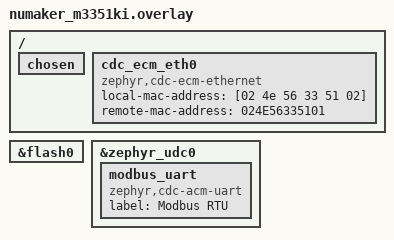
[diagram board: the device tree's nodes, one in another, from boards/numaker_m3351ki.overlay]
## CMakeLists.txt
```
cmake_minimum_required(VERSION 3.28)
find_package(Zephyr REQUIRED HINTS $ENV{ZEPHYR_BASE})
project(nv_modbus)
add_subdirectory(lib/modbus)
target_sources(app PRIVATE src/main.c src/demo_data.c src/usb.c src/network.c)
target_include_directories(app PRIVATE src)
```

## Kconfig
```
mainmenu "NK-M3351KI Modbus migration"

menu "Application"
config APP_MODBUS_CLIENT
	bool "Run master/client demonstration instead of server"
	default n
config APP_SEPARATE_REGIONS
	bool "Use the upstream separate-region example map"
	default n
config APP_LARGE_TEST_MAP
	bool "Enlarge shared map to 128 words for packet-boundary testing"
	depends on !APP_SEPARATE_REGIONS
	default n
config APP_USB_VID
	hex "Assigned application USB vendor ID"
	range 0x0 0xffff
	default 0
	help
	  Set your assigned identity in a private configuration overlay.
	  A zero identity permits compile checks but prevents USB startup.
config APP_USB_PID
	hex "Assigned application USB product ID"
	range 0x0 0xffff
	default 0
config APP_IP_ADDRESS
	string "Board private USB-network IPv4 address"
	default "192.168.77.2"
config APP_PEER_ADDRESS
	string "PC private USB-network IPv4 address"
	default "192.168.77.1"
config APP_PEER_PORT
	int "PC Modbus server TCP port"
	range 1 65535
	default 1502
config APP_QUERY_INTERVAL_MS
	int "Client query interval in milliseconds"
	range 10 60000
	default 100
endmenu

rsource "lib/modbus/Kconfig"
source "Kconfig.zephyr"
```

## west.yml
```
manifest:
  version: "1.2"
  projects:
    - name: zephyr
      url: https://github.com/zephyrproject-rtos/zephyr
      revision: 5c71a733110403a2e01f6cabd922b5f0198e9981
      path: .deps/zephyr
      west-commands: scripts/west-commands.yml
    - name: cmsis
      url: https://github.com/zephyrproject-rtos/cmsis
      revision: 512cc7e895e8491696b61f7ba8066b4a182569b8
      path: .deps/modules/hal/cmsis
    - name: cmsis_6
      url: https://github.com/zephyrproject-rtos/CMSIS_6
      revision: 1c1840af7a7e757d6e2fec3ddb0e5ce0dfcc93c8
      path: .deps/modules/hal/cmsis_6
    - name: hal_nuvoton
      url: https://github.com/zephyrproject-rtos/hal_nuvoton
      revision: 0f411a85da7d17a612d54450f608f4d30cdb971f
      path: .deps/modules/hal/nuvoton
  self:
    path: .
```

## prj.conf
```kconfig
CONFIG_SERIAL=y
CONFIG_UART_INTERRUPT_DRIVEN=y
CONFIG_UART_LINE_CTRL=y
CONFIG_CONSOLE=y
CONFIG_UART_CONSOLE=y
CONFIG_LOG=y
CONFIG_LOG_DEFAULT_LEVEL=3
CONFIG_LOG_BUFFER_SIZE=2048
CONFIG_USB_DEVICE_STACK_NEXT=y
CONFIG_CDC_ACM_SERIAL_INITIALIZE_AT_BOOT=n
CONFIG_HWINFO=y
CONFIG_NETWORKING=y
CONFIG_NET_L2_ETHERNET=y
# The pinned M3351 Zephyr port has no entropy driver. Isolated demo only.
CONFIG_TEST_RANDOM_GENERATOR=y
CONFIG_NET_IPV4=y
CONFIG_NET_IPV6=n
CONFIG_NET_TCP=y
CONFIG_NET_UDP=n
CONFIG_NET_SOCKETS=y
CONFIG_NET_MAX_CONTEXTS=10
CONFIG_NET_MAX_CONN=10
CONFIG_NET_PKT_RX_COUNT=12
CONFIG_NET_PKT_TX_COUNT=12
CONFIG_NET_BUF_RX_COUNT=32
CONFIG_NET_BUF_TX_COUNT=32
CONFIG_NET_BUF_DATA_SIZE=128
CONFIG_MAIN_STACK_SIZE=3072
CONFIG_SYSTEM_WORKQUEUE_STACK_SIZE=2048
CONFIG_HEAP_MEM_POOL_SIZE=8192
CONFIG_THREAD_NAME=y
CONFIG_INIT_STACKS=y
CONFIG_THREAD_STACK_INFO=y
CONFIG_USE_DT_CODE_PARTITION=n
```

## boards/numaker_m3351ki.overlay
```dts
/* SPDX-License-Identifier: Apache-2.0 */
/* The confirmed M3351KJCAE uses the upstream 1 MiB APROM map.
 * This application is a directly booted APROM image, not an MCUboot image.
 */
/ {
	chosen {
		/delete-property/ zephyr,code-partition;
	};
	cdc_ecm_eth0: cdc_ecm_eth0 {
		compatible = "zephyr,cdc-ecm-ethernet";
		local-mac-address = [02 4e 56 33 51 02];
		remote-mac-address = "024E56335101";
	};
};

&flash0 {
	/delete-node/ partitions;
};
&zephyr_udc0 {
	modbus_uart: modbus_uart {
		compatible = "zephyr,cdc-acm-uart";
		label = "Modbus RTU";
	};
};
```

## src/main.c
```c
/* SPDX-License-Identifier: Apache-2.0 */
#include "app.h"
#include <zephyr/logging/log.h>
#include <zephyr/net/net_ip.h>
#include <zephyr/sys/atomic.h>

LOG_MODULE_REGISTER(app, LOG_LEVEL_INF);
static modbusHandler_t rtu, tcp;
static atomic_t handlers_ready;
K_MUTEX_DEFINE(rtu_bank_lock);
K_MUTEX_DEFINE(tcp_bank_lock);

void app_transport_reset(bool reset_network)
{
    if (atomic_get(&handlers_ready)) {
        ModbusTransportReset(&rtu);
        if (reset_network) {
            ModbusTransportReset(&tcp);
        }
    }
}

static int start_handlers(void)
{
    int error;
    rtu.uModbusType = IS_ENABLED(CONFIG_APP_MODBUS_CLIENT) ? MB_MASTER : MB_SLAVE;
    rtu.xTypeHW = USB_CDC_HW;
    rtu.port = DEVICE_DT_GET(DT_NODELABEL(modbus_uart));
    rtu.u8id = IS_ENABLED(CONFIG_APP_MODBUS_CLIENT) ? 0 : 10;
    rtu.u16timeOut = 1000;
    rtu.memory_lock = &rtu_bank_lock;
    app_data_init(&rtu.memory, 0);

    tcp.uModbusType = rtu.uModbusType;
    tcp.xTypeHW = TCP_HW;
    tcp.u8id = IS_ENABLED(CONFIG_APP_MODBUS_CLIENT) ? 0 : 1;
    tcp.u16timeOut = 1000;
    tcp.uTcpPort = 502;
    tcp.tcp_idle_ms = 40000;
    tcp.memory_lock = &tcp_bank_lock;
    app_data_init(&tcp.memory, 1);

    error = ModbusInit(&rtu);
    if (error != 0) {
        return error;
    }
    error = ModbusInit(&tcp);
    if (error == 0) {
        error = ModbusStartCDC(&rtu);
    }
    if (error == 0) {
        error = ModbusStart(&tcp);
    }
    if (error != 0) {
        ModbusStop(&rtu);
        ModbusStop(&tcp);
        return error;
    }
    atomic_set(&handlers_ready, 1);
    return 0;
}

static void run_clients(void)
{
    static const uint8_t functions[] = {5, 1, 15, 2, 6, 3, 16, 4};
    struct net_in_addr peer;
    uint32_t cycle = 0;
    if (net_addr_pton(NET_AF_INET, CONFIG_APP_PEER_ADDRESS, &peer) != 0) {
        LOG_ERR("Invalid peer IPv4 address");
        return;
    }
    for (;;) {
        for (size_t i = 0; i < ARRAY_SIZE(functions); ++i) {
            for (unsigned int transport = 0; transport < 2; ++transport) {
                uint16_t data[4] = {1, 0x1234, 0x5678, 0xabcd};
                modbus_t request = {
                    .u8id = transport == 0 ? 10 : 1,
                    .u8fct = functions[i],
                    .u16RegAdd = app_data_address(functions[i]),
                    .u16CoilsNo = (functions[i] == 5 || functions[i] == 6) ? 1 : 4,
                    .u16reg = data,
                    .u16regCapacity = ARRAY_SIZE(data),
                    .u16Port = CONFIG_APP_PEER_PORT,
                    .xIpAddress = peer.s_addr,
                    .u8clientID = 0,
                };
                int result = ModbusQueryV2(transport == 0 ? &rtu : &tcp, request);
                LOG_INF("client cycle=%u transport=%s fc=%u result=%d data0=%u",
                        cycle, transport == 0 ? "rtu" : "tcp", functions[i],
                        result, data[0]);
                k_msleep(CONFIG_APP_QUERY_INTERVAL_MS);
            }
        }
        ++cycle;
    }
}

int main(void)
{
    int error = app_network_init();
    if (error == 0) {
        error = start_handlers();
    }
    if (error == 0) {
        error = app_usb_init();
    }
    if (error != 0) {
        atomic_clear(&handlers_ready);
        ModbusStop(&rtu);
        ModbusStop(&tcp);
        LOG_ERR("Startup failed: %d", error);
        return error;
    }
    LOG_INF("Modbus %s ready: RTU id10, TCP id1 port502",
            IS_ENABLED(CONFIG_APP_MODBUS_CLIENT) ? "client" : "server");
    if (IS_ENABLED(CONFIG_APP_MODBUS_CLIENT)) {
        run_clients();
    }
    return 0;
}
```

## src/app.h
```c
/* SPDX-License-Identifier: Apache-2.0 */
#ifndef NV_MODBUS_APP_H
#define NV_MODBUS_APP_H
#include "Modbus.h"

int app_usb_init(void);
int app_network_init(void);
void app_transport_reset(bool reset_network);
void app_data_init(mb_memory_t *memory, unsigned int bank);
uint16_t app_data_address(uint8_t function);
#endif
```

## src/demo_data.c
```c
/* SPDX-License-Identifier: Apache-2.0 */
#include "app.h"
#include <string.h>

static struct {
    uint16_t shared[IS_ENABLED(CONFIG_APP_LARGE_TEST_MAP) ? 128 : 16];
    uint16_t coils[2];
    uint16_t inputs[2];
    uint16_t holding[4];
    uint16_t registers[4];
} banks[2];

void app_data_init(mb_memory_t *memory, unsigned int bank)
{
    __ASSERT_NO_MSG(bank < ARRAY_SIZE(banks));
    memset(memory, 0, sizeof(*memory));
    if (IS_ENABLED(CONFIG_APP_SEPARATE_REGIONS)) {
        memory->u16coils = banks[bank].coils;
        memory->u16coilsStartAdd = 0;
        memory->u16coilsNregs = 2;
        memory->u16discreteInputs = banks[bank].inputs;
        memory->u16discreteInputsStartAdd = 100;
        memory->u16discreteInputsNregs = 2;
        memory->u16holdingRegs = banks[bank].holding;
        memory->u16holdingRegsStartAdd = 200;
        memory->u16holdingRegsNregs = 4;
        memory->u16inputRegs = banks[bank].registers;
        memory->u16inputRegsStartAdd = 300;
        memory->u16inputRegsNregs = 4;
    } else {
        memory->u16regs = banks[bank].shared;
        memory->u16regsize = ARRAY_SIZE(banks[bank].shared);
    }
}

uint16_t app_data_address(uint8_t function)
{
    if (!IS_ENABLED(CONFIG_APP_SEPARATE_REGIONS)) {
        return 0;
    }
    switch (function) {
    case 2: return 100;
    case 3:
    case 6:
    case 16: return 200;
    case 4: return 300;
    default: return 0;
    }
}
```

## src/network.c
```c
/* SPDX-License-Identifier: Apache-2.0 */
#include "app.h"
#include <errno.h>
#include <zephyr/logging/log.h>
#include <zephyr/net/net_if.h>
#include <zephyr/net/net_ip.h>

LOG_MODULE_REGISTER(app_network, LOG_LEVEL_INF);

int app_network_init(void)
{
    const struct device *device = DEVICE_DT_GET(DT_NODELABEL(cdc_ecm_eth0));
    struct net_in_addr address, netmask;
    struct net_if *iface;
    int error;

    if (!device_is_ready(device)) {
        return -ENODEV;
    }
    iface = net_if_lookup_by_dev(device);
    if (iface == NULL ||
        net_addr_pton(NET_AF_INET, CONFIG_APP_IP_ADDRESS, &address) != 0 ||
        net_addr_pton(NET_AF_INET, "255.255.255.0", &netmask) != 0) {
        return -EINVAL;
    }
    if (net_if_ipv4_addr_add(iface, &address, NET_ADDR_MANUAL, 0) == NULL ||
        !net_if_ipv4_set_netmask_by_addr(iface, &address, &netmask)) {
        return -ENOMEM;
    }
    error = net_if_up(iface);
    if (error != 0 && error != -EALREADY) {
        return error;
    }
    LOG_INF("USB network %s/24; no gateway", CONFIG_APP_IP_ADDRESS);
    return 0;
}
```

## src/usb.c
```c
/*
 * SPDX-License-Identifier: Apache-2.0
 * USB lifecycle adapted from Zephyr samples/subsys/usb/common/sample_usbd_init.c
 * Copyright (c) 2023 Nordic Semiconductor ASA
 */
#include "app.h"
#include <errno.h>
#include <zephyr/logging/log.h>
#include <zephyr/usb/usbd.h>
#include <zephyr/usb/class/usbd_cdc_acm.h>
#include <soc.h>

LOG_MODULE_REGISTER(app_usb, LOG_LEVEL_INF);
USBD_DEVICE_DEFINE(modbus_usb, DEVICE_DT_GET(DT_NODELABEL(zephyr_udc0)),
                   CONFIG_APP_USB_VID, CONFIG_APP_USB_PID);
USBD_DESC_LANG_DEFINE(language);
USBD_DESC_MANUFACTURER_DEFINE(manufacturer, "NV-Migration");
USBD_DESC_PRODUCT_DEFINE(product, "NK-M3351 Modbus RTU + TCP");
USBD_DESC_SERIAL_NUMBER_DEFINE(serial_number);
USBD_DESC_CONFIG_DEFINE(config_description, "Modbus serial and network");
USBD_CONFIGURATION_DEFINE(fs_configuration, 0, 50, &config_description);

static void cdc_session_reset(const struct device *dev, void *user_data)
{
    ARG_UNUSED(dev);
    ARG_UNUSED(user_data);
    app_transport_reset(false);
}

/*
 * The M335x devicetree leaves HXT off, so the USBD module and the PLL both run
 * from the factory-trimmed but otherwise free-running 48 MHz HIRC, and the
 * UDC driver does not trim it. Full-speed USB needs +/-0.25 %: without trim,
 * long IN packets with unfavourable bit patterns fail CRC at the host and the
 * controller retransmits the same DATA packet indefinitely (RTU "wedge").
 * Trim HIRC against USB SOF (TRM 6.2.10). Hardware clears FREQSEL when SOF is
 * missing for RETRYCNT loops, so re-arm on every reset/configuration/resume.
 */
static void hirc_trim_arm(void)
{
    SYS->HIRCTISTS = SYS_HIRCTISTS_TFAILIF_Msk | SYS_HIRCTISTS_CLKERRIF_Msk |
                     SYS_HIRCTISTS_OVBDIF_Msk;
    SYS->HIRCTCTL = (SYS->HIRCTCTL & SYS_HIRCTCTL_BOUNDARY_Msk) |
                    SYS_HIRCTCTL_REFCKSEL_Msk |
                    (3UL << SYS_HIRCTCTL_RETRYCNT_Pos) |
                    (3UL << SYS_HIRCTCTL_LOOPSEL_Pos) |
                    (1UL << SYS_HIRCTCTL_FREQSEL_Pos);
}

static void usb_message(struct usbd_context *const context,
                        const struct usbd_msg *const message)
{
    int error = 0;
    if (message->type == USBD_MSG_RESET || message->type == USBD_MSG_VBUS_REMOVED) {
        app_transport_reset(true);
    }
    if (message->type == USBD_MSG_RESET || message->type == USBD_MSG_CONFIGURATION ||
        message->type == USBD_MSG_RESUME) {
        hirc_trim_arm();
    }
    if (usbd_can_detect_vbus(context)) {
        if (message->type == USBD_MSG_VBUS_READY) {
            error = usbd_enable(context);
        } else if (message->type == USBD_MSG_VBUS_REMOVED) {
            error = usbd_disable(context);
        }
    }
    if (error != 0) {
        LOG_ERR("USB lifecycle error: %d", error);
    }
}

int app_usb_init(void)
{
    int error;
    if (CONFIG_APP_USB_VID == 0 || CONFIG_APP_USB_PID == 0) {
        LOG_ERR("Set assigned APP_USB_VID/PID before enabling USB");
        return -EINVAL;
    }
    struct usbd_desc_node *descriptors[] = {
        &language, &manufacturer, &product, &serial_number,
    };
    for (size_t i = 0; i < ARRAY_SIZE(descriptors); ++i) {
        error = usbd_add_descriptor(&modbus_usb, descriptors[i]);
        if (error != 0) {
            return error;
        }
    }
    error = usbd_add_configuration(&modbus_usb, USBD_SPEED_FS, &fs_configuration);
    if (error != 0) {
        return error;
    }
    error = usbd_register_class(&modbus_usb, "cdc_acm_0", USBD_SPEED_FS, 1);
    if (error != 0) {
        return error;
    }
    error = usbd_register_class(&modbus_usb, "cdc_ecm_0", USBD_SPEED_FS, 1);
    if (error != 0) {
        return error;
    }
    usbd_device_set_code_triple(&modbus_usb, USBD_SPEED_FS,
                               USB_BCC_MISCELLANEOUS, 0x02, 0x01);
    usbd_self_powered(&modbus_usb, false);
    error = usbd_cdc_acm_set_session_cb(DEVICE_DT_GET(DT_NODELABEL(modbus_uart)),
                                       cdc_session_reset, NULL);
    if (error != 0) {
        return error;
    }
    error = usbd_msg_register_cb(&modbus_usb, usb_message);
    if (error == 0) {
        error = usbd_init(&modbus_usb);
    }
    if (error == 0 && !usbd_can_detect_vbus(&modbus_usb)) {
        error = usbd_enable(&modbus_usb);
    }
    return error;
}
```
